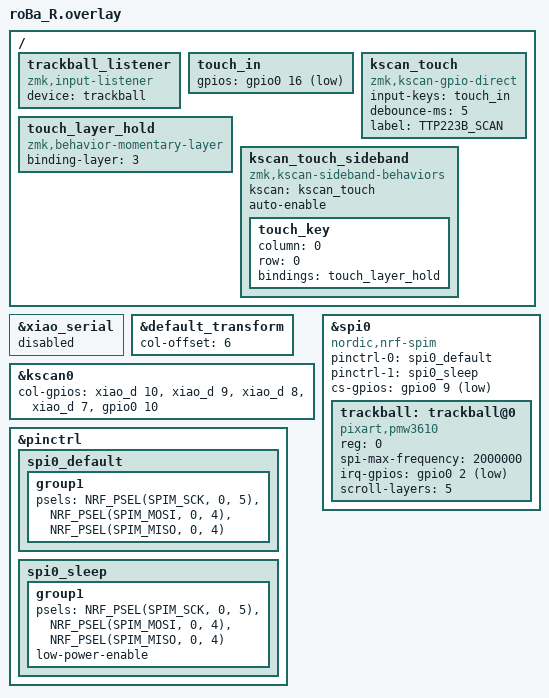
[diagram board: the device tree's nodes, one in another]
#include "roBa.dtsi"
#include <zephyr/dt-bindings/gpio/gpio.h>

&xiao_serial { status = "disabled"; };

&default_transform {
    col-offset = <6>;
};

&kscan0 {
        col-gpios
            = <&xiao_d 10 GPIO_ACTIVE_HIGH>
            , <&xiao_d 9 GPIO_ACTIVE_HIGH> 
            , <&xiao_d 8 GPIO_ACTIVE_HIGH> 
            , <&xiao_d 7 GPIO_ACTIVE_HIGH> 
            , <&gpio0 10 GPIO_ACTIVE_HIGH>
            ;
};

/ {
    trackball_listener {
        compatible = "zmk,input-listener";
        device = <&trackball>;

    };
};

&pinctrl {
    spi0_default: spi0_default {
        group1 {
            psels = <NRF_PSEL(SPIM_SCK, 0, 5)>,
                <NRF_PSEL(SPIM_MOSI, 0, 4)>,
                <NRF_PSEL(SPIM_MISO, 0, 4)>;
        };
    };

    spi0_sleep: spi0_sleep {
        group1 {
            psels = <NRF_PSEL(SPIM_SCK, 0, 5)>,
                <NRF_PSEL(SPIM_MOSI, 0, 4)>,
                <NRF_PSEL(SPIM_MISO, 0, 4)>;
            low-power-enable;
        };
    };
};

&spi0 {
    status = "okay";
    compatible = "nordic,nrf-spim";
    pinctrl-0 = <&spi0_default>;
    pinctrl-1 = <&spi0_sleep>;
    pinctrl-names = "default", "sleep";
    cs-gpios = <&gpio0 9 GPIO_ACTIVE_LOW>;

    trackball: trackball@0 {
        status = "okay";
        compatible = "pixart,pmw3610";
        reg = <0>;
        spi-max-frequency = <2000000>;
        irq-gpios = <&gpio0 2 (GPIO_ACTIVE_LOW | GPIO_PULL_UP)>;
        scroll-layers = <5>;
    };
};



/ {
    /* 1. 追加 GPIO キー定義 ---------------------------------- */
    touch_in: touch_in {
        gpios = <&gpio0 16 (GPIO_ACTIVE_LOW | GPIO_PULL_UP)>;  /* P0.16 (D7/A7) */
    };

    /* 2. 1キーだけの GPIO-Direct KSCAN ----------------------- */
    kscan_touch: kscan_touch {
        compatible = "zmk,kscan-gpio-direct";
        input-keys = <&touch_in>;
        debounce-ms = <5>;
        label = "TTP223B_SCAN";
    };

    /* 3. レイヤー Momentary ビヘイビア ----------------------- */
    touch_layer_hold: touch_layer_hold {
        compatible = "zmk,behavior-momentary-layer";
        binding-layer = <3>;           /* ← 有効にしたいレイヤー番号 */
        #binding-cells = <0>;
    };

    /* 4. side-band ラッパーで既存マトリクスと共存 ----------- */
    kscan_touch_sideband: kscan_touch_sideband {
        compatible = "zmk,kscan-sideband-behaviors";
        kscan = <&kscan_touch>;        /* ← ここで参照（& が付く） */
        auto-enable;

        touch_key {
            column = <0>;
            row    = <0>;
            bindings = <&touch_layer_hold>;
        };
    };
};
